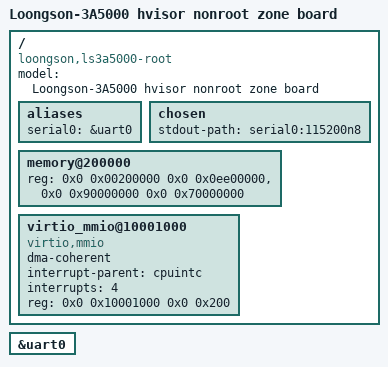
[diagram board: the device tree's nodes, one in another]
// SPDX-License-Identifier: GPL-2.0
/*
 * Copyright (C) 2023 Loongson Technology Corporation Limited
 */

/dts-v1/;

#include "loongson-3a5000.dtsi"

/ {
	compatible = "loongson,ls3a5000-root", "loongson,ls3a5000";
	model = "Loongson-3A5000 hvisor nonroot zone board";

	aliases {
		serial0 = &uart0;
	};

	chosen {
		stdout-path = "serial0:115200n8";
	};

	memory@200000 {
		device_type = "memory";
		reg = <0x0 0x00200000 0x0 0x0ee00000>,
		      <0x0 0x90000000 0x0 0x70000000>;
	};

	// virtio console
	virtio_mmio@10001000 {
		dma-coherent;
		compatible = "virtio,mmio";
		interrupt-parent = <&cpuintc>;
		interrupts = <4>; // = hwirq
		reg = <0x0 0x10001000 0x0 0x200>;
	};
};

&uart0 {
	status = "okay";
};
